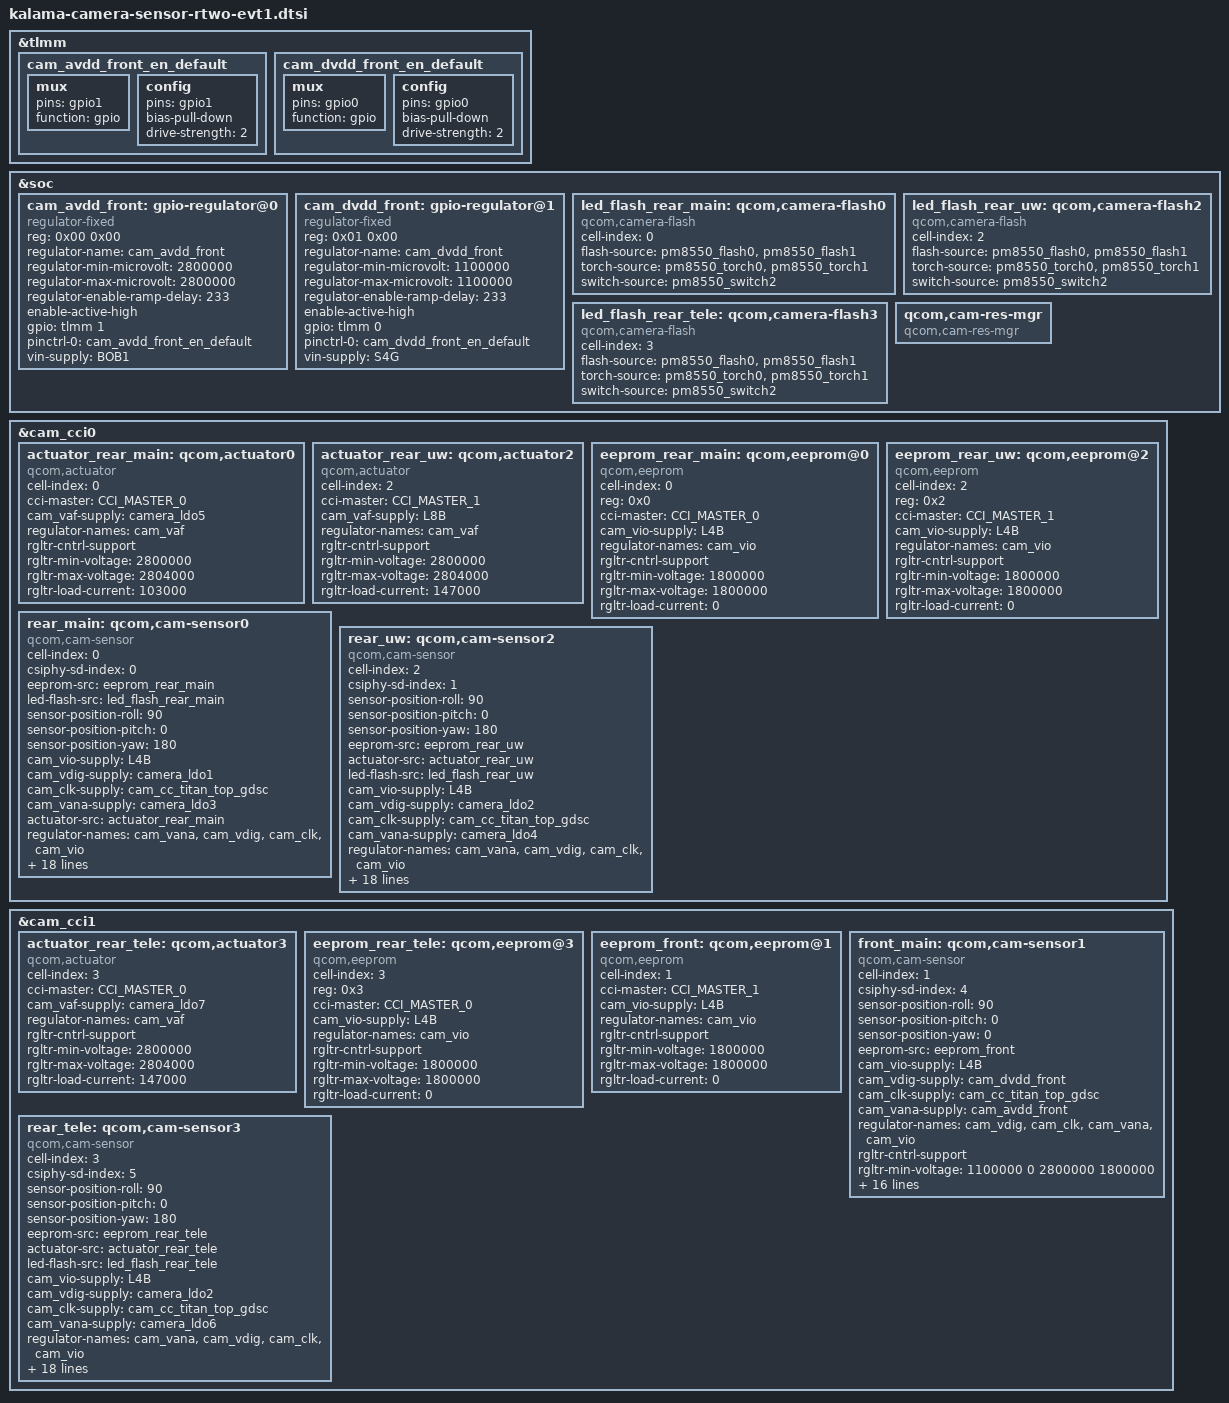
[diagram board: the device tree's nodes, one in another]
/*
   This base is derivated from kalama-camera-sensor-mtp.dtsi
*/
#include <dt-bindings/msm-camera.h>

&tlmm {
	cam_avdd_front_en_default: cam_avdd_front_en_default {
		mux {
			pins = "gpio1";
			function = "gpio";
		};

		config {
			pins = "gpio1";
			bias-pull-down; /* PULL DOWN */
			drive-strength = <2>; /* 2 MA */
		};
	};

	cam_dvdd_front_en_default: cam_dvdd_front_en_default {
		mux {
			pins = "gpio0";
			function = "gpio";
		};

		config {
			pins = "gpio0";
			bias-pull-down; /* PULL DOWN */
			drive-strength = <2>; /* 2 MA */
		};
	};
};

&soc {
	cam_avdd_front: gpio-regulator@0 {
		compatible = "regulator-fixed";
		reg = <0x00 0x00>;
		regulator-name = "cam_avdd_front";
		regulator-min-microvolt = <2800000>;
		regulator-max-microvolt = <2800000>;
		regulator-enable-ramp-delay = <233>;
		enable-active-high;
		gpio = <&tlmm 1 0>;
		pinctrl-names = "default";
		pinctrl-0 = <&cam_avdd_front_en_default>;
		vin-supply = <&BOB1>;
	};

	cam_dvdd_front: gpio-regulator@1 {
		compatible = "regulator-fixed";
		reg = <0x01 0x00>;
		regulator-name = "cam_dvdd_front";
		regulator-min-microvolt = <1100000>;
		regulator-max-microvolt = <1100000>;
		regulator-enable-ramp-delay = <233>;
		enable-active-high;
		gpio = <&tlmm 0 0>;
		pinctrl-names = "default";
		pinctrl-0 = <&cam_dvdd_front_en_default>;
		vin-supply = <&S4G>;
	};

	led_flash_rear_main: qcom,camera-flash0 {
		cell-index = <0>;
		compatible = "qcom,camera-flash";
		flash-source = <&pm8550_flash0 &pm8550_flash1>;
		torch-source = <&pm8550_torch0 &pm8550_torch1>;
		switch-source = <&pm8550_switch2>;
		status = "ok";
	};

	led_flash_rear_uw: qcom,camera-flash2 {
		cell-index = <2>;
		compatible = "qcom,camera-flash";
		flash-source = <&pm8550_flash0 &pm8550_flash1>;
		torch-source = <&pm8550_torch0 &pm8550_torch1>;
		switch-source = <&pm8550_switch2>;
		status = "ok";
	};

	led_flash_rear_tele: qcom,camera-flash3 {
		cell-index = <3>;
		compatible = "qcom,camera-flash";
		flash-source = <&pm8550_flash0 &pm8550_flash1>;
		torch-source = <&pm8550_torch0 &pm8550_torch1>;
		switch-source = <&pm8550_switch2>;
		status = "ok";
	};

	qcom,cam-res-mgr {
		compatible = "qcom,cam-res-mgr";
		status = "ok";
	};
};

&cam_cci0 {
	actuator_rear_main: qcom,actuator0 {
		cell-index = <0>;
		compatible = "qcom,actuator";
		cci-master = <CCI_MASTER_0>;
		cam_vaf-supply = <&camera_ldo5>;
		regulator-names = "cam_vaf";
		rgltr-cntrl-support;
		rgltr-min-voltage = <2800000>;
		rgltr-max-voltage = <2804000>;
		rgltr-load-current = <103000>;
		status = "ok";
	};

	actuator_rear_uw: qcom,actuator2{
		cell-index = <2>;
		compatible = "qcom,actuator";
		cci-master = <CCI_MASTER_1>;
		cam_vaf-supply = <&L8B>;
		regulator-names = "cam_vaf";
		rgltr-cntrl-support;
		rgltr-min-voltage = <2800000>;
		rgltr-max-voltage = <2804000>;
		rgltr-load-current = <147000>;
		status = "ok";
	};

	eeprom_rear_main: qcom,eeprom@0 {
		cell-index = <0>;
		reg = <0x0>;
		compatible = "qcom,eeprom";
		cci-master = <CCI_MASTER_0>;
		cam_vio-supply = <&L4B>;
		regulator-names = "cam_vio";
		rgltr-cntrl-support;
		rgltr-min-voltage = <1800000>;
		rgltr-max-voltage = <1800000>;
		rgltr-load-current = <0>;
	};

 	eeprom_rear_uw: qcom,eeprom@2 {
		cell-index = <2>;
		reg = <0x2>;
		compatible = "qcom,eeprom";
		cci-master = <CCI_MASTER_1>;
		cam_vio-supply = <&L4B>;
		regulator-names = "cam_vio";
		rgltr-cntrl-support;
		rgltr-min-voltage = <1800000>;
		rgltr-max-voltage = <1800000>;
		rgltr-load-current = <0>;
	};

	rear_main: qcom,cam-sensor0 {
		cell-index = <0>;
		compatible = "qcom,cam-sensor";
		csiphy-sd-index = <0>;
		eeprom-src = <&eeprom_rear_main>;
		led-flash-src = <&led_flash_rear_main>;
		sensor-position-roll = <90>;
		sensor-position-pitch = <0>;
		sensor-position-yaw = <180>;

		cam_vio-supply = <&L4B>;
		cam_vdig-supply = <&camera_ldo1>;
		cam_clk-supply = <&cam_cc_titan_top_gdsc>;
		cam_vana-supply = <&camera_ldo3>;
		actuator-src = <&actuator_rear_main>;
		//cam_vaf-supply = <&L16B>;
		regulator-names = "cam_vana",
			"cam_vdig","cam_clk","cam_vio";
		rgltr-cntrl-support;
		rgltr-min-voltage = <2800000 1100000 0 1800000>;
		rgltr-max-voltage = <2804000 1104000 0 1800000>;
		rgltr-load-current = <132000 405000 0 3000>;

		gpio-no-mux = <0>;
		pinctrl-names = "cam_default", "cam_suspend";
		pinctrl-0 = <&cam_sensor_mclk1_active
			&cam_sensor_active_rst1>;
		pinctrl-1 = <&cam_sensor_mclk1_suspend
			&cam_sensor_suspend_rst1>;
		gpios = <&tlmm 101 0>,
			<&tlmm 117 0>;
		gpio-reset = <1>;
		gpio-req-tbl-num = <0 1>;
		gpio-req-tbl-flags = <1 0>;
		gpio-req-tbl-label = "CAMIF_MCLK1",
					"CAM_RESET1";
		cci-master = <CCI_MASTER_0>;
		clocks = <&camcc CAM_CC_MCLK1_CLK>;
		clock-names = "cam_clk";
		clock-cntl-level = "nominal";
		clock-rates = <24000000>;
		status = "ok";
	};

	rear_uw:qcom,cam-sensor2 {
		cell-index = <2>;
		compatible = "qcom,cam-sensor";
		csiphy-sd-index = <1>;
		sensor-position-roll = <90>;
		sensor-position-pitch = <0>;
		sensor-position-yaw = <180>;
		eeprom-src = <&eeprom_rear_uw>;
		actuator-src = <&actuator_rear_uw>;
		led-flash-src = <&led_flash_rear_uw>;
		cam_vio-supply = <&L4B>;
		cam_vdig-supply = <&camera_ldo2>;
		cam_clk-supply = <&cam_cc_titan_top_gdsc>;
		cam_vana-supply = <&camera_ldo4>;
		//cam_vaf-supply = <&L8B>;
		regulator-names = "cam_vana",
			"cam_vdig", "cam_clk","cam_vio";
		rgltr-cntrl-support;
		rgltr-min-voltage = <2800000 1056000 0 1800000>;
		rgltr-max-voltage = <2804000 1060000 0 1800000>;
		rgltr-load-current = <148000 212000 0 3000>;
		gpio-no-mux = <0>;
		pinctrl-names = "cam_default", "cam_suspend";
		pinctrl-0 = <&cam_sensor_mclk2_active
				 &cam_sensor_active_rst2>;
		pinctrl-1 = <&cam_sensor_mclk2_suspend
				 &cam_sensor_suspend_rst2>;
		gpios = <&tlmm 102 0>,
			<&tlmm 118 0>;
		gpio-reset = <1>;
		gpio-req-tbl-num = <0 1>;
		gpio-req-tbl-flags = <1 0>;
		gpio-req-tbl-label = "CAMIF_MCLK2",
					"CAM_RESET2";
		cci-master = <CCI_MASTER_1>;
		clocks = <&camcc CAM_CC_MCLK2_CLK>;
		clock-names = "cam_clk";
		clock-cntl-level = "nominal";
		clock-rates = <24000000>;
		status = "ok";
	};
};

&cam_cci1 {
	actuator_rear_tele: qcom,actuator3{
		cell-index = <3>;
		compatible = "qcom,actuator";
		cci-master = <CCI_MASTER_0>;
		cam_vaf-supply = <&camera_ldo7>;
		regulator-names = "cam_vaf";
		rgltr-cntrl-support;
		rgltr-min-voltage = <2800000>;
		rgltr-max-voltage = <2804000>;
		rgltr-load-current = <147000>;
		status = "ok";
	};

	eeprom_rear_tele: qcom,eeprom@3 {
		cell-index = <3>;
		reg = <0x3>;
		compatible = "qcom,eeprom";
		cci-master = <CCI_MASTER_0>;
		cam_vio-supply = <&L4B>;
		regulator-names = "cam_vio";
		rgltr-cntrl-support;
		rgltr-min-voltage = <1800000>;
		rgltr-max-voltage = <1800000>;
		rgltr-load-current = <0>;
	};

	eeprom_front: qcom,eeprom@1 {
		cell-index = <1>;
		compatible = "qcom,eeprom";
		cci-master = <CCI_MASTER_1>;
		cam_vio-supply = <&L4B>;
		regulator-names = "cam_vio";
		rgltr-cntrl-support;
		rgltr-min-voltage = <1800000>;
		rgltr-max-voltage = <1800000>;
		rgltr-load-current = <0>;
		status = "ok";
	};

	front_main: qcom,cam-sensor1 {
		cell-index = <1>;
		compatible = "qcom,cam-sensor";
		csiphy-sd-index = <4>;
		sensor-position-roll = <90>;
		sensor-position-pitch = <0>;
		sensor-position-yaw = <0>;
		eeprom-src = <&eeprom_front>;
		cam_vio-supply = <&L4B>;
		cam_vdig-supply = <&cam_dvdd_front>;
		cam_clk-supply = <&cam_cc_titan_top_gdsc>;
		cam_vana-supply = <&cam_avdd_front>;
		regulator-names = "cam_vdig",
			"cam_clk", "cam_vana","cam_vio";
		rgltr-cntrl-support;
		rgltr-min-voltage = <1100000 0 2800000 1800000>;
		rgltr-max-voltage = <1100000 0 2800000 1800000>;
		rgltr-load-current = <125000 0 95000 3000>;
		gpio-no-mux = <0>;
		pinctrl-names = "cam_default", "cam_suspend";
		pinctrl-0 = <&cam_sensor_mclk4_active
			&cam_sensor_active_rst4>;
		pinctrl-1 = <&cam_sensor_mclk4_suspend
			&cam_sensor_suspend_rst4>;
		gpios = <&tlmm 104 0>,
			<&tlmm 120 0>;
		gpio-reset = <1>;
		gpio-req-tbl-num = <0 1>;
		gpio-req-tbl-flags = <1 0>;
		gpio-req-tbl-label = "CAMIF_MCLK4",
					"CAM_RESET4";
		cci-master = <CCI_MASTER_1>;
		clocks = <&camcc CAM_CC_MCLK4_CLK>;
		clock-names = "cam_clk";
		clock-cntl-level = "nominal";
		clock-rates = <24000000>;
		status = "ok";
	};

	rear_tele:qcom,cam-sensor3 {
		cell-index = <3>;
		compatible = "qcom,cam-sensor";
		csiphy-sd-index = <5>;
		sensor-position-roll = <90>;
		sensor-position-pitch = <0>;
		sensor-position-yaw = <180>;
		eeprom-src = <&eeprom_rear_tele>;
		actuator-src = <&actuator_rear_tele>;
		led-flash-src = <&led_flash_rear_tele>;
		cam_vio-supply = <&L4B>;
		cam_vdig-supply = <&camera_ldo2>;
		cam_clk-supply = <&cam_cc_titan_top_gdsc>;
		cam_vana-supply = <&camera_ldo6>;
		//cam_vaf-supply = <&camera_ldo7>;
		regulator-names = "cam_vana",
			"cam_vdig", "cam_clk","cam_vio";
		rgltr-cntrl-support;
		rgltr-min-voltage = <2800000 1056000 0 1800000>;
		rgltr-max-voltage = <2804000 1060000 0 1800000>;
		rgltr-load-current = <159000 79000 0 3000>;
		gpio-no-mux = <0>;
		pinctrl-names = "cam_default", "cam_suspend";
		pinctrl-0 = <&cam_sensor_mclk3_active
				 &cam_sensor_active_rst3>;
		pinctrl-1 = <&cam_sensor_mclk3_suspend
				 &cam_sensor_suspend_rst3>;
		gpios = <&tlmm 103 0>,
			<&tlmm 119 0>;
		gpio-reset = <1>;
		gpio-req-tbl-num = <0 1>;
		gpio-req-tbl-flags = <1 0>;
		gpio-req-tbl-label = "CAMIF_MCLK3",
					"CAM_RESET3";
		cci-master = <CCI_MASTER_0>;
		clocks = <&camcc CAM_CC_MCLK3_CLK>;
		clock-names = "cam_clk";
		clock-cntl-level = "nominal";
		clock-rates = <24000000>;
		status = "ok";
	};
};
